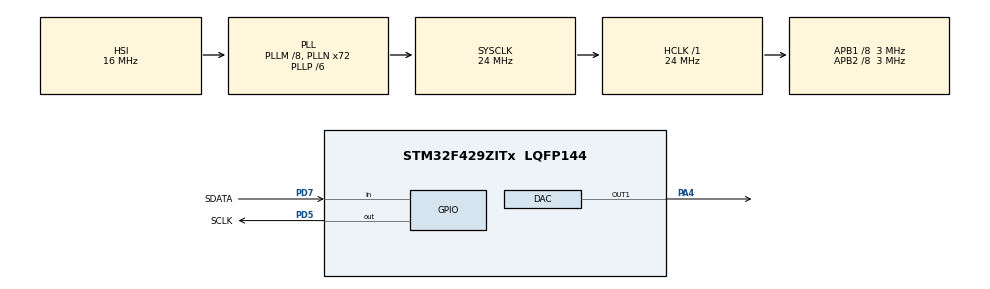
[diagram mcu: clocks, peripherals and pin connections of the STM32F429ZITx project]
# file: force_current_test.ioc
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Mcu.Family=STM32F4
Mcu.Name=STM32F429ZITx
Mcu.Package=LQFP144
NVIC.PriorityGroup=NVIC_PRIORITYGROUP_4
PA13.Mode=Trace_Asynchronous_SW
PA13.Signal=SYS_JTMS-SWDIO
PA14.Mode=Trace_Asynchronous_SW
PA14.Signal=SYS_JTCK-SWCLK
PA4.Signal=COMP_DAC1_group
PB3.Mode=Trace_Asynchronous_SW
PB3.Signal=SYS_JTDO-SWO
PD5.GPIO_Label=SCLK
PD5.Signal=GPIO_Output
PD7.GPIO_Label=SDATA
PD7.Signal=GPIO_Input
ProjectManager.HeapSize=0x200
ProjectManager.StackSize=0x400
ProjectManager.TargetToolchain=STM32CubeIDE
RCC.48MHZClocksFreq_Value=36000000
RCC.AHBFreq_Value=24000000
RCC.APB1CLKDivider=RCC_HCLK_DIV8
RCC.APB1Freq_Value=3000000
RCC.APB1TimFreq_Value=6000000
RCC.APB2CLKDivider=RCC_HCLK_DIV8
RCC.APB2Freq_Value=3000000
RCC.APB2TimFreq_Value=6000000
RCC.CortexFreq_Value=24000000
RCC.HCLKFreq_Value=24000000
RCC.HSE_VALUE=25000000
RCC.HSI_VALUE=16000000
RCC.LSE_VALUE=32768
RCC.PLLM=8
RCC.PLLN=72
RCC.PLLP=RCC_PLLP_DIV6
RCC.SYSCLKFreq_VALUE=24000000
RCC.SYSCLKSource=RCC_SYSCLKSOURCE_PLLCLK
RCC.VCOOutputFreq_Value=144000000
SH.COMP_DAC1_group.0=DAC_OUT1,DAC_OUT1
board=custom

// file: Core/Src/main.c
/* USER CODE BEGIN Header */
/**
  ******************************************************************************
  * @file           : main.c
  * @brief          : Main program body
  ******************************************************************************
  * @attention
  *
  * <h2><center>&copy; Copyright (c) 2020 STMicroelectronics.
  * All rights reserved.</center></h2>
  *
  * This software component is licensed by ST under BSD 3-Clause license,
  * the "License"; You may not use this file except in compliance with the
  * License. You may obtain a copy of the License at:
  *                        opensource.org/licenses/BSD-3-Clause
  *
  ******************************************************************************
  */
/* USER CODE END Header */
#include "main.h"

/* USER CODE BEGIN Includes */
#include <stdio.h>
/* USER CODE END Includes */

/* USER CODE BEGIN PTD */
int32_t value;
int32_t newvalue;
/* USER CODE END PTD */

DAC_HandleTypeDef hdac;

void SystemClock_Config(void);
static void MX_GPIO_Init(void);
static void MX_DAC_Init(void);

/* USER CODE BEGIN 0 */
int32_t CB_SPI_Receive (void) {

int32_t buffer = 0U;

int i, j, k = 1;

// wait for SDATA to go lo
while (!HAL_GPIO_ReadPin (SDATA_GPIO_Port, SDATA_Pin)) ;
while (HAL_GPIO_ReadPin (SDATA_GPIO_Port, SDATA_Pin)) ;

// wait 300 ns
for (j = 0; j < 5; j++) k += 19;

// read 24 data bits
for (i = 0; i < 24; i++) {
  HAL_GPIO_WritePin (SCLK_GPIO_Port, SCLK_Pin, GPIO_PIN_SET);
  buffer <<= 1;
  HAL_GPIO_WritePin (SCLK_GPIO_Port, SCLK_Pin, GPIO_PIN_RESET);
  buffer += HAL_GPIO_ReadPin (SDATA_GPIO_Port, SDATA_Pin);
}

buffer = (buffer << 8) >> 8; //Shifting up to pick up sign bit

// generate one or 3 more clock pulse to set gain for next sample and set bit 23 before returning
HAL_GPIO_WritePin (SCLK_GPIO_Port, SCLK_Pin, GPIO_PIN_SET);
HAL_GPIO_WritePin (SCLK_GPIO_Port, SCLK_Pin, GPIO_PIN_RESET);

return buffer;

}
/* USER CODE END 0 */

int main(void)
{

  /* MCU Configuration--------------------------------------------------------*/

  /* Reset of all peripherals, Initializes the Flash interface and the Systick. */
  HAL_Init();

  /* Configure the system clock */
  SystemClock_Config();

  /* Initialize all configured peripherals */
  MX_GPIO_Init();
  MX_DAC_Init();
  /* USER CODE BEGIN 2 */

  int32_t calval = 0;

  for(int i=0; i < 10; i++){
	  calval += CB_SPI_Receive();
	  HAL_Delay(100);
  }
  calval /= 10;

  /* USER CODE END 2 */

  /* Infinite loop */
  /* USER CODE BEGIN WHILE */
  while (1)
  {
	  ITM_SendChar('c');

		value = CB_SPI_Receive ();
		newvalue = value - calval;

		//DAC1->DHR12L1 = 0xFFF;
		//HAL_Delay(100);
		//DAC1->DHR12L1 = 0x000;

		DAC -> CR |= DAC_CR_EN1;
		DAC -> DHR12R1 = newvalue;
    /* USER CODE END WHILE */

  }
}

void SystemClock_Config(void)
{
  RCC_OscInitTypeDef RCC_OscInitStruct = {0};
  RCC_ClkInitTypeDef RCC_ClkInitStruct = {0};

  /** Configure the main internal regulator output voltage
  */
  __HAL_RCC_PWR_CLK_ENABLE();
  __HAL_PWR_VOLTAGESCALING_CONFIG(PWR_REGULATOR_VOLTAGE_SCALE3);
  /** Initializes the RCC Oscillators according to the specified parameters
  * in the RCC_OscInitTypeDef structure.
  */
  RCC_OscInitStruct.OscillatorType = RCC_OSCILLATORTYPE_HSI;
  RCC_OscInitStruct.HSIState = RCC_HSI_ON;
  RCC_OscInitStruct.HSICalibrationValue = RCC_HSICALIBRATION_DEFAULT;
  RCC_OscInitStruct.PLL.PLLState = RCC_PLL_ON;
  RCC_OscInitStruct.PLL.PLLSource = RCC_PLLSOURCE_HSI;
  RCC_OscInitStruct.PLL.PLLM = 8;
  RCC_OscInitStruct.PLL.PLLN = 72;
  RCC_OscInitStruct.PLL.PLLP = RCC_PLLP_DIV6;
  RCC_OscInitStruct.PLL.PLLQ = 4;
  if (HAL_RCC_OscConfig(&RCC_OscInitStruct) != HAL_OK)
  {
    Error_Handler();
  }
  /** Initializes the CPU, AHB and APB buses clocks
  */
  RCC_ClkInitStruct.ClockType = RCC_CLOCKTYPE_HCLK|RCC_CLOCKTYPE_SYSCLK
                              |RCC_CLOCKTYPE_PCLK1|RCC_CLOCKTYPE_PCLK2;
  RCC_ClkInitStruct.SYSCLKSource = RCC_SYSCLKSOURCE_PLLCLK;
  RCC_ClkInitStruct.AHBCLKDivider = RCC_SYSCLK_DIV1;
  RCC_ClkInitStruct.APB1CLKDivider = RCC_HCLK_DIV8;
  RCC_ClkInitStruct.APB2CLKDivider = RCC_HCLK_DIV8;

  if (HAL_RCC_ClockConfig(&RCC_ClkInitStruct, FLASH_LATENCY_0) != HAL_OK)
  {
    Error_Handler();
  }
}

static void MX_DAC_Init(void)
{

  DAC_ChannelConfTypeDef sConfig = {0};

  /** DAC Initialization
  */
  hdac.Instance = DAC;
  if (HAL_DAC_Init(&hdac) != HAL_OK)
  {
    Error_Handler();
  }
  /** DAC channel OUT1 config
  */
  sConfig.DAC_Trigger = DAC_TRIGGER_NONE;
  sConfig.DAC_OutputBuffer = DAC_OUTPUTBUFFER_ENABLE;
  if (HAL_DAC_ConfigChannel(&hdac, &sConfig, DAC_CHANNEL_1) != HAL_OK)
  {
    Error_Handler();
  }

}

static void MX_GPIO_Init(void)
{
  GPIO_InitTypeDef GPIO_InitStruct = {0};

  /* GPIO Ports Clock Enable */
  __HAL_RCC_GPIOA_CLK_ENABLE();
  __HAL_RCC_GPIOD_CLK_ENABLE();
  __HAL_RCC_GPIOB_CLK_ENABLE();

  /*Configure GPIO pin Output Level */
  HAL_GPIO_WritePin(SCLK_GPIO_Port, SCLK_Pin, GPIO_PIN_RESET);

  /*Configure GPIO pin : SCLK_Pin */
  GPIO_InitStruct.Pin = SCLK_Pin;
  GPIO_InitStruct.Mode = GPIO_MODE_OUTPUT_PP;
  GPIO_InitStruct.Pull = GPIO_NOPULL;
  GPIO_InitStruct.Speed = GPIO_SPEED_FREQ_LOW;
  HAL_GPIO_Init(SCLK_GPIO_Port, &GPIO_InitStruct);

  /*Configure GPIO pin : SDATA_Pin */
  GPIO_InitStruct.Pin = SDATA_Pin;
  GPIO_InitStruct.Mode = GPIO_MODE_INPUT;
  GPIO_InitStruct.Pull = GPIO_NOPULL;
  HAL_GPIO_Init(SDATA_GPIO_Port, &GPIO_InitStruct);

}

void Error_Handler(void)
{
}

/************************ (C) COPYRIGHT STMicroelectronics *****END OF FILE****/
